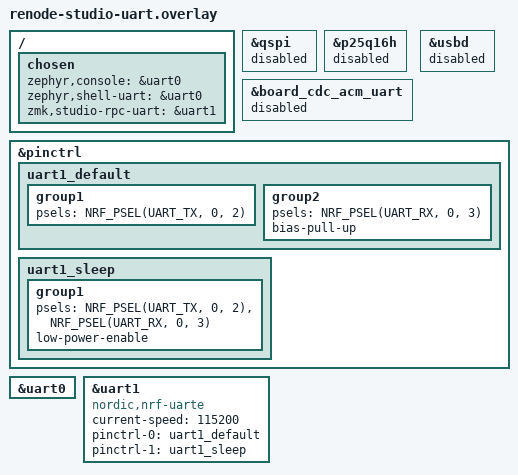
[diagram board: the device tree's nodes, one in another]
/*
 * Renode-friendly Studio-RPC-over-UART overlay for the XIAO nRF52840.
 *
 * NB: nRF52840/XIAO-specific. This overlay disables `&usbd`/`&qspi`/
 * `&p25q16h` (nodes that only exist on this SoC/board family) and points
 * uart1 at pins (P0.02/P0.03) that are specific to the XIAO nRF52840
 * board file. A board/SoC outside that family needs its own overlay (see
 * `overlays/split-wired-uart.overlay` for the split-role sibling, and
 * skills/test-zmk-renode/SKILL.md for the general pattern) -- this snippet
 * is deliberately named `renode-studio-uart`, not something board-generic.
 *
 * Real hardware normally carries ZMK Studio RPC over USB-CDC-ACM (the
 * `studio-rpc-usb-uart` snippet in dependencies/zmk/app/snippets/). Renode's
 * nRF52840 USBD model does not present a host-openable CDC port, so for
 * emulation we bind `zmk,studio-rpc-uart` (and the console) to real hardware
 * UART peripherals instead. The RPC byte framing on the wire is identical
 * either way (see dependencies/zmk/app/src/studio/uart_rpc_transport.c) —
 * only the physical carrier changes.
 *
 * The stock xiao_ble ZMK board file disables the only routed-to-a-header
 * UART (`xiao_serial`, i.e. &uart0) because real XIAO boards normally use
 * USB for console+Studio. This overlay re-enables uart0 for the console and
 * brings up uart1 (present in the nRF52840 SoC but unused/unrouted on the
 * stock XIAO board file) for Studio RPC.
 *
 * NB: the uart1 pinctrl below points at pins (P0.02/P0.03) that are not
 * broken out on a real XIAO board and are not verified conflict-free with
 * other on-board peripherals. This overlay is for Renode emulation only —
 * do NOT flash a build using it to real hardware. Renode's UART peripheral
 * model does not care about GPIO/pin routing; it only needs the devicetree
 * node to exist and be enabled.
 *
 * Renode gotcha: the XIAO board dts enables &qspi (the external p25q16h NOR
 * flash chip) by default. Renode does not model the QSPI peripheral's
 * EVENTS_READY, so the nrfx QSPI driver's init busy-waits on it forever and
 * the firmware hangs before it ever reaches main() / prints a boot banner —
 * with no crash or error, just infinite silence. This chip is not ZMK's
 * settings/keymap backend (that's the internal flash_controller via
 * zephyr,flash = &flash0), so it is safe to disable for emulation.
 */

&qspi {
    status = "disabled";
};

/* Disabling the qspi bus node above does NOT auto-disable this child flash
 * device node (devicetree status does not cascade to children) — Zephyr
 * still sees DT_HAS_NORDIC_QSPI_NOR_ENABLED=y from p25q16h alone and builds
 * the nordic_qspi_nor driver, whose init still pokes the (disabled) QSPI
 * peripheral's real register addresses directly and hangs the same way.
 * Must disable both nodes. */
&p25q16h {
    status = "disabled";
};

/* Same class of bug again: xiao_ble_common.dtsi unconditionally includes
 * <boards/common/usb/cdc_acm_serial.dtsi>, which enables a USB-CDC-ACM UART
 * node (`board_cdc_acm_uart`, child of &usbd) regardless of which snippet
 * you use. We don't reference it (we point zephyr,console/zmk,studio-rpc-uart
 * at real UARTs above), but merely being "okay" is enough for Zephyr to
 * build+init its driver, which busy-waits on USBD:EVENTCAUSE — a real USB
 * host attach event Renode's USBD model never generates — hanging boot the
 * same way QSPI did. Disable both the CDC ACM child node and the usbd bus.
 */
&board_cdc_acm_uart {
    status = "disabled";
};

&usbd {
    status = "disabled";
};

&pinctrl {
    uart1_default: uart1_default {
        group1 {
            psels = <NRF_PSEL(UART_TX, 0, 2)>;
        };
        group2 {
            psels = <NRF_PSEL(UART_RX, 0, 3)>;
            bias-pull-up;
        };
    };

    uart1_sleep: uart1_sleep {
        group1 {
            psels = <NRF_PSEL(UART_TX, 0, 2)>,
                    <NRF_PSEL(UART_RX, 0, 3)>;
            low-power-enable;
        };
    };
};

&uart0 {
    status = "okay";
};

&uart1 {
    compatible = "nordic,nrf-uarte";
    status = "okay";
    current-speed = <115200>;
    pinctrl-0 = <&uart1_default>;
    pinctrl-1 = <&uart1_sleep>;
    pinctrl-names = "default", "sleep";
};

/ {
    chosen {
        zephyr,console = &uart0;
        zephyr,shell-uart = &uart0;
        zmk,studio-rpc-uart = &uart1;
    };
};
